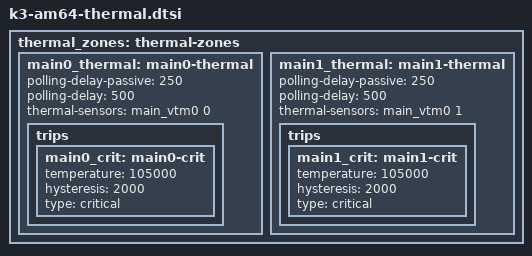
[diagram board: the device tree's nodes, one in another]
// SPDX-License-Identifier: GPL-2.0

#include <dt-bindings/thermal/thermal.h>

thermal_zones: thermal-zones {
	main0_thermal: main0-thermal {
		polling-delay-passive = <250>;	/* milliSeconds */
		polling-delay = <500>;		/* milliSeconds */
		thermal-sensors = <&main_vtm0 0>;

		trips {
			main0_crit: main0-crit {
				temperature = <105000>;	/* milliCelsius */
				hysteresis = <2000>;	/* milliCelsius */
				type = "critical";
			};
		};
	};

	main1_thermal: main1-thermal {
		polling-delay-passive = <250>;	/* milliSeconds */
		polling-delay = <500>;		/* milliSeconds */
		thermal-sensors = <&main_vtm0 1>;

		trips {
			main1_crit: main1-crit {
				temperature = <105000>;	/* milliCelsius */
				hysteresis = <2000>;	/* milliCelsius */
				type = "critical";
			};
		};
	};
};
